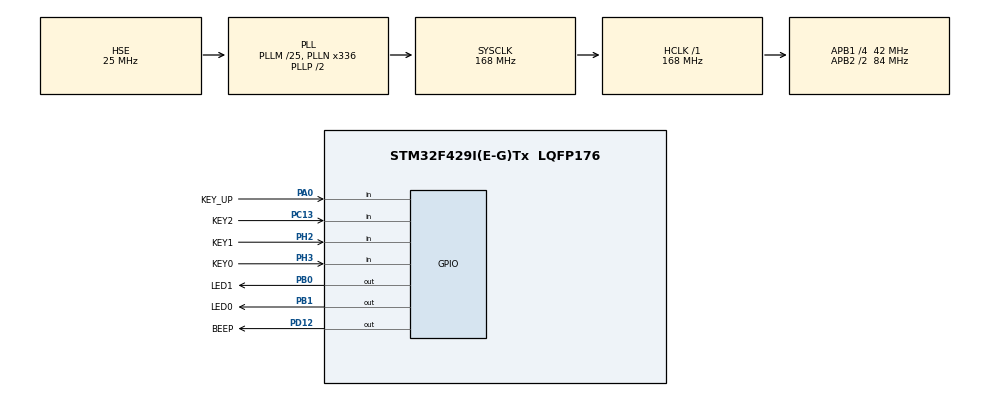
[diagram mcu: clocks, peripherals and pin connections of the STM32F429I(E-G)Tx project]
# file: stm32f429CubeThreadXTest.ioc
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Mcu.Family=STM32F4
Mcu.Name=STM32F429I(E-G)Tx
Mcu.Package=LQFP176
NVIC.PriorityGroup=NVIC_PRIORITYGROUP_4
PA0/WKUP.GPIO_Label=KEY_UP
PA0/WKUP.GPIO_PuPd=GPIO_PULLDOWN
PA0/WKUP.Signal=GPIO_Input
PA13.Mode=Serial_Wire
PA13.Signal=SYS_JTMS-SWDIO
PA14.Mode=Serial_Wire
PA14.Signal=SYS_JTCK-SWCLK
PB0.GPIO_Label=LED1
PB0.GPIO_PuPd=GPIO_PULLUP
PB0.GPIO_Speed=GPIO_SPEED_FREQ_VERY_HIGH
PB0.PinState=GPIO_PIN_SET
PB0.Signal=GPIO_Output
PB1.GPIO_Label=LED0
PB1.GPIO_PuPd=GPIO_PULLUP
PB1.GPIO_Speed=GPIO_SPEED_FREQ_VERY_HIGH
PB1.PinState=GPIO_PIN_SET
PB1.Signal=GPIO_Output
PC13.GPIO_Label=KEY2
PC13.GPIO_PuPd=GPIO_PULLUP
PC13.Signal=GPIO_Input
PC14/OSC32_IN.Mode=LSE-External-Oscillator
PC14/OSC32_IN.Signal=RCC_OSC32_IN
PC15/OSC32_OUT.Mode=LSE-External-Oscillator
PC15/OSC32_OUT.Signal=RCC_OSC32_OUT
PD12.GPIO_Label=BEEP
PD12.GPIO_ModeDefaultOutputPP=GPIO_MODE_OUTPUT_PP
PD12.GPIO_PuPd=GPIO_PULLDOWN
PD12.GPIO_Speed=GPIO_SPEED_FREQ_VERY_HIGH
PD12.PinState=GPIO_PIN_SET
PD12.Signal=GPIO_Output
PH0/OSC_IN.Mode=HSE-External-Oscillator
PH0/OSC_IN.Signal=RCC_OSC_IN
PH1/OSC_OUT.Mode=HSE-External-Oscillator
PH1/OSC_OUT.Signal=RCC_OSC_OUT
PH2.GPIO_Label=KEY1
PH2.GPIO_PuPd=GPIO_PULLUP
PH2.Signal=GPIO_Input
PH3.GPIO_Label=KEY0
PH3.GPIO_PuPd=GPIO_PULLUP
PH3.Signal=GPIO_Input
ProjectManager.HeapSize=0x200
ProjectManager.StackSize=0x400
ProjectManager.TargetToolchain=STM32CubeIDE
RCC.48MHZClocksFreq_Value=48000000
RCC.AHBFreq_Value=168000000
RCC.APB1CLKDivider=RCC_HCLK_DIV4
RCC.APB1Freq_Value=42000000
RCC.APB1TimFreq_Value=84000000
RCC.APB2CLKDivider=RCC_HCLK_DIV2
RCC.APB2Freq_Value=84000000
RCC.APB2TimFreq_Value=168000000
RCC.CortexFreq_Value=168000000
RCC.EnbaleCSS=true
RCC.HCLKFreq_Value=168000000
RCC.HSE_VALUE=25000000
RCC.HSI_VALUE=16000000
RCC.PLLM=25
RCC.PLLN=336
RCC.PLLQ=7
RCC.PLLSourceVirtual=RCC_PLLSOURCE_HSE
RCC.RCC_RTC_Clock_Source=RCC_RTCCLKSOURCE_LSE
RCC.RCC_RTC_Clock_SourceVirtual=RCC_RTCCLKSOURCE_LSE
RCC.SYSCLKFreq_VALUE=168000000
RCC.SYSCLKSource=RCC_SYSCLKSOURCE_PLLCLK
RCC.VCOOutputFreq_Value=336000000
board=custom

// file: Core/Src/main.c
/* USER CODE BEGIN Header */
/**
 ******************************************************************************
 * @file           : main.c
 * @brief          : Main program body
 ******************************************************************************
 * @attention
 *
 * <h2><center>&copy; Copyright (c) 2021 STMicroelectronics.
 * All rights reserved.</center></h2>
 *
 * This software component is licensed by ST under BSD 3-Clause license,
 * the "License"; You may not use this file except in compliance with the
 * License. You may obtain a copy of the License at:
 *                        opensource.org/licenses/BSD-3-Clause
 *
 ******************************************************************************
 */
/* USER CODE END Header */
#include "main.h"
#include "gpio.h"

/* USER CODE BEGIN Includes */

#include "tx_api.h"

/* USER CODE END Includes */

void SystemClock_Config(void);

int main(void)
{

    /* MCU Configuration------------------------------------------------------*/

    /* Reset of all peripherals, Initializes the Flash interface and the
     * Systick. */
    HAL_Init();

    /* USER CODE BEGIN Init */
    HAL_RCC_DeInit();
    /* USER CODE END Init */

    /* Configure the system clock */
    SystemClock_Config();

    /* Initialize all configured peripherals */
    MX_GPIO_Init();
    /* USER CODE BEGIN 2 */

    // Start ThreadX RTOS, do not use infinite loop
    _tx_initialize_kernel_enter();

    /* USER CODE END 2 */

    /* Infinite loop */
    /* USER CODE BEGIN WHILE */

    // while loop have been removed****************

    /* USER CODE END WHILE */

    /* USER CODE BEGIN 3 */

    // while loop have been removed****************

    /* USER CODE END 3 */
}

void SystemClock_Config(void)
{
    RCC_OscInitTypeDef RCC_OscInitStruct = {0};
    RCC_ClkInitTypeDef RCC_ClkInitStruct = {0};

    /** Configure the main internal regulator output voltage
     */
    __HAL_RCC_PWR_CLK_ENABLE();
    __HAL_PWR_VOLTAGESCALING_CONFIG(PWR_REGULATOR_VOLTAGE_SCALE1);
    /** Initializes the RCC Oscillators according to the specified parameters
     * in the RCC_OscInitTypeDef structure.
     */
    RCC_OscInitStruct.OscillatorType = RCC_OSCILLATORTYPE_HSE;
    RCC_OscInitStruct.HSEState       = RCC_HSE_ON;
    RCC_OscInitStruct.PLL.PLLState   = RCC_PLL_ON;
    RCC_OscInitStruct.PLL.PLLSource  = RCC_PLLSOURCE_HSE;
    RCC_OscInitStruct.PLL.PLLM       = 25;
    RCC_OscInitStruct.PLL.PLLN       = 336;
    RCC_OscInitStruct.PLL.PLLP       = RCC_PLLP_DIV2;
    RCC_OscInitStruct.PLL.PLLQ       = 7;
    if (HAL_RCC_OscConfig(&RCC_OscInitStruct) != HAL_OK)
    {
        Error_Handler();
    }
    /** Initializes the CPU, AHB and APB buses clocks
     */
    RCC_ClkInitStruct.ClockType = RCC_CLOCKTYPE_HCLK | RCC_CLOCKTYPE_SYSCLK |
                                  RCC_CLOCKTYPE_PCLK1 | RCC_CLOCKTYPE_PCLK2;
    RCC_ClkInitStruct.SYSCLKSource   = RCC_SYSCLKSOURCE_PLLCLK;
    RCC_ClkInitStruct.AHBCLKDivider  = RCC_SYSCLK_DIV1;
    RCC_ClkInitStruct.APB1CLKDivider = RCC_HCLK_DIV4;
    RCC_ClkInitStruct.APB2CLKDivider = RCC_HCLK_DIV2;

    if (HAL_RCC_ClockConfig(&RCC_ClkInitStruct, FLASH_LATENCY_5) != HAL_OK)
    {
        Error_Handler();
    }
    /** Enables the Clock Security System
     */
    HAL_RCC_EnableCSS();
}

void Error_Handler(void)
{
    /* USER CODE BEGIN Error_Handler_Debug */
    /* User can add his own implementation to report the HAL error return state
     */
    __disable_irq();
    while (1) {}
    /* USER CODE END Error_Handler_Debug */
}

#ifdef USE_FULL_ASSERT
/**
 * @brief  Reports the name of the source file and the source line number
 *         where the assert_param error has occurred.
 * @param  file: pointer to the source file name
 * @param  line: assert_param error line source number
 * @retval None
 */
void assert_failed(uint8_t* file, uint32_t line)
{
    /* USER CODE BEGIN 6 */
    /* User can add his own implementation to report the file name and line
       number, ex: printf("Wrong parameters value: file %s on line %d\r\n",
       file, line) */
    /* USER CODE END 6 */
}
#endif /* USE_FULL_ASSERT */

/************************ (C) COPYRIGHT STMicroelectronics *****END OF FILE****/
